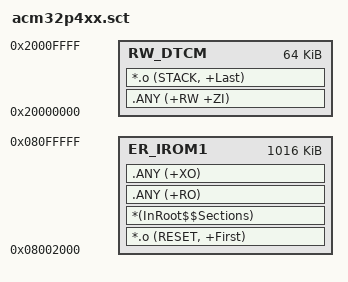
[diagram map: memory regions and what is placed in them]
; *************************************************************
; *** ACM32P4XX — DTCM only (SRAM1/PSRAM managed at runtime)***
; *************************************************************
; DTCM  0x20000000-0x2000FFFF  64KB   RW/ZI + stack
; SRAM1 0x20010000-0x2001FFFF  64KB   heap (rt_system_heap_init)
; PSRAM 0x80000000-0x801FFFFF  2MB    psram memheap
; *************************************************************

LR_IROM1 0x08002000 0x000FE000 {
  ER_IROM1 0x08002000 0x000FE000 {
   *.o (RESET, +First)
   *(InRoot$$Sections)
   .ANY (+RO)
   .ANY (+XO)
  }
  RW_DTCM 0x20000000 0x00010000 {
   .ANY (+RW +ZI)
   *.o (STACK, +Last)
  }
}
